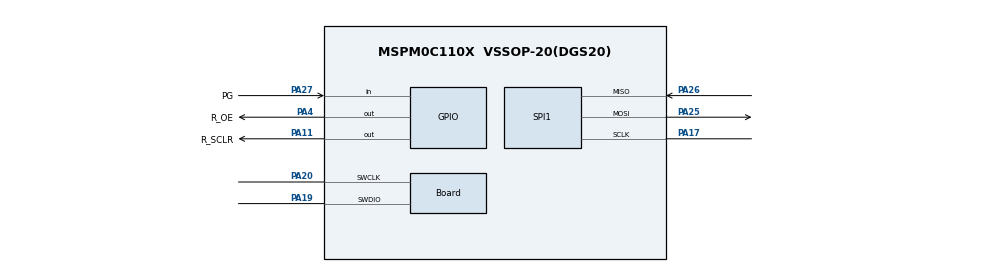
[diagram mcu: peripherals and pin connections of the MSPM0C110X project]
/**
 * @cliArgs --device "MSPM0C110X" --part "Default" --package "VSSOP-20(DGS20)" --product "mspm0_sdk@2.05.01.01"
 * @versions {"tool":"1.24.0+4110"}
 */

/**
 * Import the modules used in this configuration.
 */
const GPIO   = scripting.addModule("/ti/driverlib/GPIO", {}, false);
const GPIO1  = GPIO.addInstance();
const GPIO2  = GPIO.addInstance();
const SPI    = scripting.addModule("/ti/driverlib/SPI", {}, false);
const SPI1   = SPI.addInstance();
const SYSCTL = scripting.addModule("/ti/driverlib/SYSCTL");

/**
 * Write custom configuration values to the imported modules.
 */
GPIO1.$name                          = "GPIO_LEDS";
GPIO1.associatedPins.create(2);
GPIO1.associatedPins[0].$name        = "USER_LED_1";
GPIO1.associatedPins[0].initialValue = "SET";
GPIO1.associatedPins[0].assignedPin  = "22";
GPIO1.associatedPins[1].$name        = "USER_TEST";
GPIO1.associatedPins[1].assignedPin  = "2";
GPIO1.associatedPins[1].initialValue = "SET";

const Board                       = scripting.addModule("/ti/driverlib/Board", {}, false);
Board.peripheral.$assign          = "DEBUGSS";
Board.peripheral.swclkPin.$assign = "PA20";
Board.peripheral.swdioPin.$assign = "PA19";

GPIO2.$name                          = "GPIO_EXTRA";
GPIO2.associatedPins.create(4);
GPIO2.associatedPins[0].$name        = "R_SCLR";
GPIO2.associatedPins[0].ioStructure  = "SD";
GPIO2.associatedPins[0].initialValue = "SET";
GPIO2.associatedPins[0].pin.$assign  = "PA11";
GPIO2.associatedPins[1].$name        = "PG";
GPIO2.associatedPins[1].direction    = "INPUT";
GPIO2.associatedPins[1].ioStructure  = "SD";
GPIO2.associatedPins[1].pin.$assign  = "PA27";
GPIO2.associatedPins[2].$name        = "R_LATCH";
GPIO2.associatedPins[3].$name        = "R_OE";
GPIO2.associatedPins[3].ioStructure  = "SD";
GPIO2.associatedPins[3].pin.$assign  = "PA4";

SPI1.$name                      = "SPI_0";
SPI1.targetBitRate              = 100000;
SPI1.enabledInterrupts          = ["RX"];
SPI1.rxFifoThreshold            = "DL_SPI_RX_FIFO_LEVEL_ONE_FRAME";
SPI1.txFifoThreshold            = "DL_SPI_TX_FIFO_LEVEL_EMPTY";
SPI1.frameFormat                = "MOTO3";
SPI1.sclkPinConfig.$name        = "ti_driverlib_gpio_GPIOPinGeneric0";
SPI1.mosiPinConfig.$name        = "ti_driverlib_gpio_GPIOPinGeneric1";
SPI1.misoPinConfig.$name        = "ti_driverlib_gpio_GPIOPinGeneric2";
SPI1.peripheral.sclkPin.$assign = "PA17";
SPI1.peripheral.mosiPin.$assign = "PA25";
SPI1.peripheral.misoPin.$assign = "PA26";

SYSCTL.clockTreeEn = true;

/**
 * Pinmux solution for unlocked pins/peripherals. This ensures that minor changes to the automatic solver in a future
 * version of the tool will not impact the pinmux you originally saw.  These lines can be completely deleted in order to
 * re-solve from scratch.
 */
GPIO1.associatedPins[0].pin.$suggestSolution = "PA22";
GPIO1.associatedPins[1].pin.$suggestSolution = "PA2";
GPIO2.associatedPins[2].pin.$suggestSolution = "PA28";
SPI1.peripheral.$suggestSolution             = "SPI0";
